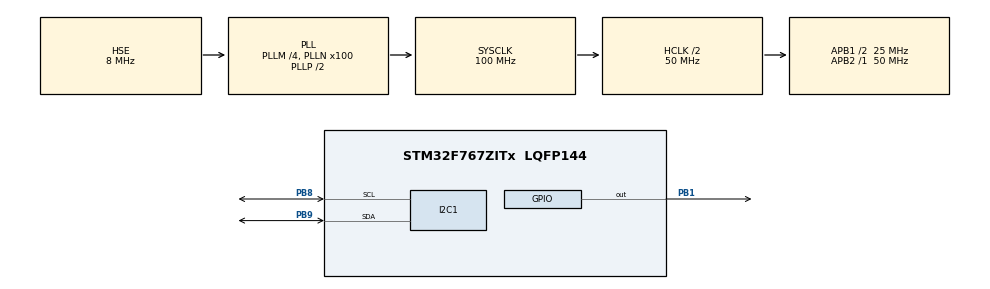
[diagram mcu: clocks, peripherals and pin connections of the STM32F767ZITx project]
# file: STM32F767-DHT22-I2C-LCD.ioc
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I2C1.Timing=0x00606092
Mcu.Family=STM32F7
Mcu.Name=STM32F767ZITx
Mcu.Package=LQFP144
NVIC.PriorityGroup=NVIC_PRIORITYGROUP_4
PA13.Mode=Serial_Wire
PA13.Signal=SYS_JTMS-SWDIO
PA14.Mode=Serial_Wire
PA14.Signal=SYS_JTCK-SWCLK
PB1.Signal=GPIO_Output
PB8.Mode=I2C
PB8.Signal=I2C1_SCL
PB9.Mode=I2C
PB9.Signal=I2C1_SDA
PH0/OSC_IN.Mode=HSE-External-Oscillator
PH0/OSC_IN.Signal=RCC_OSC_IN
PH1/OSC_OUT.Mode=HSE-External-Oscillator
PH1/OSC_OUT.Signal=RCC_OSC_OUT
ProjectManager.HeapSize=0x200
ProjectManager.StackSize=0x400
ProjectManager.TargetToolchain=STM32CubeIDE
RCC.48MHZClocksFreq_Value=24000000
RCC.AHBCLKDivider=RCC_SYSCLK_DIV2
RCC.AHBFreq_Value=50000000
RCC.APB1CLKDivider=RCC_HCLK_DIV2
RCC.APB1Freq_Value=25000000
RCC.APB1TimFreq_Value=50000000
RCC.APB2Freq_Value=50000000
RCC.APB2TimFreq_Value=50000000
RCC.CortexFreq_Value=50000000
RCC.HCLKFreq_Value=50000000
RCC.HSE_VALUE=8000000
RCC.HSI_VALUE=16000000
RCC.PLLM=4
RCC.PLLMUL=RCC_PLL_MUL9
RCC.PLLN=100
RCC.PLLQ=4
RCC.PLLSourceVirtual=RCC_PLLSOURCE_HSE
RCC.PRESCALERUSB=RCC_USBCLKSOURCE_PLL_DIV1_5
RCC.SYSCLKFreq_VALUE=100000000
RCC.SYSCLKSource=RCC_SYSCLKSOURCE_PLLCLK
RCC.SYSCLKSourceVirtual=RCC_SYSCLKSOURCE_PLLCLK
RCC.USBFreq_Value=50000000
RCC.VCOOutputFreq_Value=200000000
TIM6.Prescaler=50-1
VP_TIM6_VS_ClockSourceINT.Mode=Enable_Timer
board=NUCLEO-F767ZI

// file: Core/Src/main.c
/* USER CODE BEGIN Header */
/**
  ******************************************************************************
  * @file           : main.c
  * @brief          : Main program body
  ******************************************************************************
  * @attention
  *
  * Copyright (c) 2026 STMicroelectronics.
  * All rights reserved.
  *
  * This software is licensed under terms that can be found in the LICENSE file
  * in the root directory of this software component.
  * If no LICENSE file comes with this software, it is provided AS-IS.
  *
  ******************************************************************************
  */
/* USER CODE END Header */
#include "main.h"

/* USER CODE BEGIN Includes */
#include "i2c-lcd.h"
#include "stdio.h"
/* USER CODE END Includes */

I2C_HandleTypeDef hi2c1;

TIM_HandleTypeDef htim6;

void SystemClock_Config(void);
static void MX_GPIO_Init(void);
static void MX_I2C1_Init(void);
static void MX_TIM6_Init(void);

/* USER CODE BEGIN 0 */
/* --- Microsecond delay using TIM6 --- */
void delay_us (uint16_t us)
{
	/*change your code here for the delay in microseconds*/
	__HAL_TIM_SET_COUNTER(&htim6, 0); // reset counter
	while ((__HAL_TIM_GET_COUNTER(&htim6)) < us); // wait until counter reaches us
}

void Display_Temp  (float Temp)
{
	char str[20] = {0};
	lcd_put_cur(0,0);

	sprintf (str, "TEMP: %.2f ", Temp);
	lcd_send_string(str);
	lcd_send_data('C');
}

void Display_Rh  (float Rh)
{
	char str[20] = {0};
	lcd_put_cur(1,0);

	sprintf (str, "RH: %.2f ", Rh);
	lcd_send_string(str);
	lcd_send_data('%');
}

float Temperature = 0;
float Humidity = 0;
uint8_t Presence = 0;

void Set_Pin_Output (GPIO_TypeDef *GPIOx, uint16_t GPIO_Pin)
{
	GPIO_InitTypeDef GPIO_InitStruct = {0};
	GPIO_InitStruct.Pin = GPIO_Pin;
	GPIO_InitStruct.Mode = GPIO_MODE_OUTPUT_OD;
	GPIO_InitStruct.Speed = GPIO_SPEED_FREQ_LOW;
	HAL_GPIO_Init(GPIOx, &GPIO_InitStruct);
}

void Set_Pin_Input (GPIO_TypeDef *GPIOx, uint16_t GPIO_Pin)
{
	GPIO_InitTypeDef GPIO_InitStruct = {0};
	GPIO_InitStruct.Pin = GPIO_Pin;
	GPIO_InitStruct.Mode = GPIO_MODE_INPUT;
	GPIO_InitStruct.Speed = GPIO_NOPULL;
	HAL_GPIO_Init(GPIOx, &GPIO_InitStruct);
}

/**************************** DHT22 FUNCTION ************************************/
#define DHT22_PORT GPIOB
#define DHT22_PIN GPIO_PIN_1

/* --- Start DHT22 --- */
void DHT22_Start (void)
{
	Set_Pin_Output(DHT22_PORT, DHT22_PIN); // set the pin as output
	HAL_GPIO_WritePin(DHT22_PORT, DHT22_PIN, 0); // pulls the pin low
	delay_us(1200); // wait for > 1ms

	HAL_GPIO_WritePin(DHT22_PORT, DHT22_PIN, 1); // pulls the pin high
	delay_us(20); // wait for 30us

	Set_Pin_Input(DHT22_PORT, DHT22_PIN); // set as input
}

/* --- Check DHT22 response --- */
uint8_t DHT22_Check_Response(void)
{
	uint8_t Response = 0;
	delay_us(40); // wait for 40us
	if (!(HAL_GPIO_ReadPin (DHT22_PORT, DHT22_PIN))) // if pin is low
	{
		delay_us(80); // wait for 80us

		if ((HAL_GPIO_ReadPin (DHT22_PORT, DHT22_PIN))) Response = 1; // if the pin is high, response is ok
		else Response = 0;
	}

	while ((HAL_GPIO_ReadPin (DHT22_PORT, DHT22_PIN))); // wait for the pin to go low
	return Response;
}

/* --- Read 1 byte from DHT22 --- */
uint8_t DHT22_Read (void)
{
    uint8_t i = 0;
    uint8_t j;
    uint32_t timeout;

    for (j = 0; j < 8; j++)
    {
    	timeout = 0;
        while (!HAL_GPIO_ReadPin(DHT22_PORT, DHT22_PIN)) // wait for HIGH
        {
        	if (++timeout > 1000) return 0;
        }
        delay_us(40);                                       // 40 µs

        if (HAL_GPIO_ReadPin(DHT22_PORT, DHT22_PIN))
        	i |= (1 << (7 - j));

        timeout = 0;
        while (HAL_GPIO_ReadPin(DHT22_PORT, DHT22_PIN))
        {
        	if (++timeout > 1000) return 0;
        }

    }
    return i;
}

/* --- Read Temperature & Humidity --- */
uint8_t DHT22_Read_Data(float *Temperature, float *Humidity)
{
    uint8_t Rh_byte1, Rh_byte2, Temp_byte1, Temp_byte2, SUM;
    uint16_t RH, TEMP;
    uint8_t Presence;

    DHT22_Start();
    Presence = DHT22_Check_Response();
    if(Presence != 1) return 0; // no response

    Rh_byte1   = DHT22_Read();
    Rh_byte2   = DHT22_Read();
    Temp_byte1 = DHT22_Read();
    Temp_byte2 = DHT22_Read();
    SUM        = DHT22_Read();

    // Correct checksum: sum modulo 256
    if (((Rh_byte1 + Rh_byte2 + Temp_byte1 + Temp_byte2) & 0xFF) != SUM)
        return 0; // checksum fail

    RH   = (Rh_byte1 << 8) | Rh_byte2;
    TEMP = (Temp_byte1 << 8) | Temp_byte2;

    *Humidity    = RH / 10.0;
    *Temperature = TEMP / 10.0;

    return 1; // success
}

/* USER CODE END 0 */

int main(void)
{

  /* MCU Configuration--------------------------------------------------------*/

  /* Reset of all peripherals, Initializes the Flash interface and the Systick. */
  HAL_Init();

  /* Configure the system clock */
  SystemClock_Config();

  /* Initialize all configured peripherals */
  MX_GPIO_Init();
  MX_I2C1_Init();
  MX_TIM6_Init();
  /* USER CODE BEGIN 2 */

  HAL_TIM_Base_Start(&htim6);

  lcd_init();
  lcd_send_string ("Initializing....");
  HAL_Delay(2000);
  lcd_clear();

  /* USER CODE END 2 */

  /* Infinite loop */
  while (1)
  {

    /* USER CODE BEGIN 3 */
	    if(DHT22_Read_Data(&Temperature, &Humidity))
	    {
	        Display_Temp(Temperature);
	        Display_Rh(Humidity);
	    }
	    else
	    {
	        lcd_clear();
	        lcd_put_cur(0,0);
	        lcd_send_string("Checksum/Error");
	    }
	    HAL_Delay(2000); // wait 2s
  }
  /* USER CODE END 3 */
}

void SystemClock_Config(void)
{
  RCC_OscInitTypeDef RCC_OscInitStruct = {0};
  RCC_ClkInitTypeDef RCC_ClkInitStruct = {0};

  /** Configure the main internal regulator output voltage
  */
  __HAL_RCC_PWR_CLK_ENABLE();
  __HAL_PWR_VOLTAGESCALING_CONFIG(PWR_REGULATOR_VOLTAGE_SCALE3);

  /** Initializes the RCC Oscillators according to the specified parameters
  * in the RCC_OscInitTypeDef structure.
  */
  RCC_OscInitStruct.OscillatorType = RCC_OSCILLATORTYPE_HSE;
  RCC_OscInitStruct.HSEState = RCC_HSE_ON;
  RCC_OscInitStruct.PLL.PLLState = RCC_PLL_ON;
  RCC_OscInitStruct.PLL.PLLSource = RCC_PLLSOURCE_HSE;
  RCC_OscInitStruct.PLL.PLLM = 4;
  RCC_OscInitStruct.PLL.PLLN = 100;
  RCC_OscInitStruct.PLL.PLLP = RCC_PLLP_DIV2;
  RCC_OscInitStruct.PLL.PLLQ = 4;
  RCC_OscInitStruct.PLL.PLLR = 2;
  if (HAL_RCC_OscConfig(&RCC_OscInitStruct) != HAL_OK)
  {
    Error_Handler();
  }

  /** Initializes the CPU, AHB and APB buses clocks
  */
  RCC_ClkInitStruct.ClockType = RCC_CLOCKTYPE_HCLK|RCC_CLOCKTYPE_SYSCLK
                              |RCC_CLOCKTYPE_PCLK1|RCC_CLOCKTYPE_PCLK2;
  RCC_ClkInitStruct.SYSCLKSource = RCC_SYSCLKSOURCE_PLLCLK;
  RCC_ClkInitStruct.AHBCLKDivider = RCC_SYSCLK_DIV2;
  RCC_ClkInitStruct.APB1CLKDivider = RCC_HCLK_DIV2;
  RCC_ClkInitStruct.APB2CLKDivider = RCC_HCLK_DIV1;

  if (HAL_RCC_ClockConfig(&RCC_ClkInitStruct, FLASH_LATENCY_1) != HAL_OK)
  {
    Error_Handler();
  }
}

static void MX_I2C1_Init(void)
{

  hi2c1.Instance = I2C1;
  hi2c1.Init.Timing = 0x00606092;
  hi2c1.Init.OwnAddress1 = 0;
  hi2c1.Init.AddressingMode = I2C_ADDRESSINGMODE_7BIT;
  hi2c1.Init.DualAddressMode = I2C_DUALADDRESS_DISABLE;
  hi2c1.Init.OwnAddress2 = 0;
  hi2c1.Init.OwnAddress2Masks = I2C_OA2_NOMASK;
  hi2c1.Init.GeneralCallMode = I2C_GENERALCALL_DISABLE;
  hi2c1.Init.NoStretchMode = I2C_NOSTRETCH_DISABLE;
  if (HAL_I2C_Init(&hi2c1) != HAL_OK)
  {
    Error_Handler();
  }

  /** Configure Analogue filter
  */
  if (HAL_I2CEx_ConfigAnalogFilter(&hi2c1, I2C_ANALOGFILTER_ENABLE) != HAL_OK)
  {
    Error_Handler();
  }

  /** Configure Digital filter
  */
  if (HAL_I2CEx_ConfigDigitalFilter(&hi2c1, 0) != HAL_OK)
  {
    Error_Handler();
  }

}

static void MX_TIM6_Init(void)
{

  TIM_MasterConfigTypeDef sMasterConfig = {0};

  htim6.Instance = TIM6;
  htim6.Init.Prescaler = 50-1;
  htim6.Init.CounterMode = TIM_COUNTERMODE_UP;
  htim6.Init.Period = 65535;
  htim6.Init.AutoReloadPreload = TIM_AUTORELOAD_PRELOAD_DISABLE;
  if (HAL_TIM_Base_Init(&htim6) != HAL_OK)
  {
    Error_Handler();
  }
  sMasterConfig.MasterOutputTrigger = TIM_TRGO_RESET;
  sMasterConfig.MasterSlaveMode = TIM_MASTERSLAVEMODE_DISABLE;
  if (HAL_TIMEx_MasterConfigSynchronization(&htim6, &sMasterConfig) != HAL_OK)
  {
    Error_Handler();
  }

}

static void MX_GPIO_Init(void)
{
  GPIO_InitTypeDef GPIO_InitStruct = {0};

  /* GPIO Ports Clock Enable */
  __HAL_RCC_GPIOH_CLK_ENABLE();
  __HAL_RCC_GPIOB_CLK_ENABLE();
  __HAL_RCC_GPIOA_CLK_ENABLE();

  /*Configure GPIO pin Output Level */
  HAL_GPIO_WritePin(GPIOB, GPIO_PIN_1, GPIO_PIN_RESET);

  /*Configure GPIO pin : PB1 */
  GPIO_InitStruct.Pin = GPIO_PIN_1;
  GPIO_InitStruct.Mode = GPIO_MODE_OUTPUT_PP;
  GPIO_InitStruct.Pull = GPIO_NOPULL;
  GPIO_InitStruct.Speed = GPIO_SPEED_FREQ_LOW;
  HAL_GPIO_Init(GPIOB, &GPIO_InitStruct);

}

void Error_Handler(void)
{
  __disable_irq();
  while (1)
  {
  }
}
